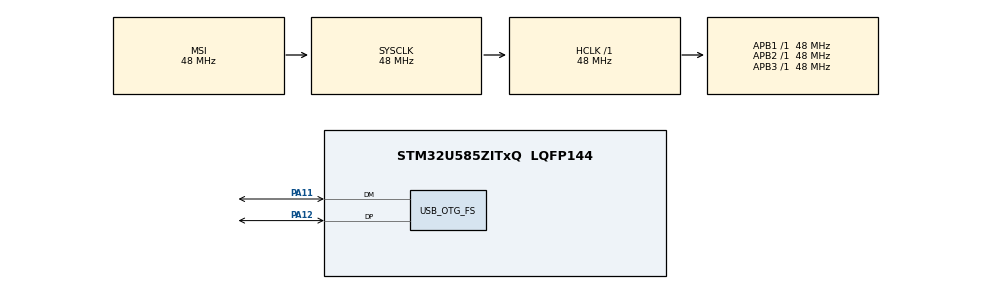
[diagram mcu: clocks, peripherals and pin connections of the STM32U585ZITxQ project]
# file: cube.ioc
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CORTEX_M33_NS.userName=CORTEX_M33
Mcu.Family=STM32U5
Mcu.Name=STM32U585ZITxQ
Mcu.Package=LQFP144
NVIC.OTG_FS_IRQn=true\:0\:0\:false\:false\:true\:true\:true\:true
NVIC.PriorityGroup=NVIC_PRIORITYGROUP_4
NVIC.TIM3_IRQn=true\:0\:0\:true\:false\:true\:false\:true\:true
NVIC.TimeBase=TIM3_IRQn
NVIC.TimeBaseIP=TIM3
PA11.Mode=Device_Only
PA11.Signal=USB_OTG_FS_DM
PA12.Mode=Device_Only
PA12.Signal=USB_OTG_FS_DP
PA13\ (JTMS/SWDIO).Mode=Serial_Wire
PA13\ (JTMS/SWDIO).Signal=DEBUG_JTMS-SWDIO
PA14\ (JTCK/SWCLK).Mode=Serial_Wire
PA14\ (JTCK/SWCLK).Signal=DEBUG_JTCK-SWCLK
PWR.PowerMode=PWR_SMPS_SUPPLY
ProjectManager.HeapSize=0x0
ProjectManager.StackSize=0x400
ProjectManager.TargetToolchain=STM32CubeIDE
RCC.ADCFreq_Value=16000000
RCC.AHBFreq_Value=48000000
RCC.APB1Freq_Value=48000000
RCC.APB1TimFreq_Value=48000000
RCC.APB2Freq_Value=48000000
RCC.APB2TimFreq_Value=48000000
RCC.APB3Freq_Value=48000000
RCC.CortexFreq_Value=48000000
RCC.DACCLockSelectionVirtual=RCC_DAC1CLKSOURCE_LSI
RCC.DACCLockSelectionVirtualString=RCC_DAC1CLKSOURCE_LSI
RCC.EPOD_VALUE=48000000
RCC.HCLKFreq_Value=48000000
RCC.HSE_VALUE=16000000
RCC.HSI48_VALUE=48000000
RCC.HSI_VALUE=16000000
RCC.LSE_VALUE=32768
RCC.LSIDIV_VALUE=32000
RCC.MSIClockRange=RCC_MSIRANGE_0
RCC.MSI_VALUE=48000000
RCC.SYSCLKFreq_VALUE=48000000
RCC.USBFreq_Value=48000000
RCC.VCOOutputFreq_Value=6192000000
USB_OTG_FS.VirtualMode=Device_Only
VP_ICACHE_VS_ICACHE.Mode=DirectMappedCache
VP_LPBAMQUEUE_VS_QUEUE.Mode=QUEUEMODE
VP_LPBAM_VS_SIG1.Mode=SmartRun
VP_LPBAM_VS_SIG4.Mode=LPDMA1
VP_PWR_VS_DBSignals.Mode=DisableDeadBatterySignals
VP_PWR_VS_LPOM.Mode=PowerOptimisation
VP_PWR_VS_SECSignals.Mode=Security/Privilege
VP_SYS_VS_tim3.Mode=TIM3
board=custom

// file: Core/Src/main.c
/* USER CODE BEGIN Header */
/**
  ******************************************************************************
  * @file           : main.c
  * @brief          : Main program body
  ******************************************************************************
  * @attention
  *
  * Copyright (c) 2023 STMicroelectronics.
  * All rights reserved.
  *
  * This software is licensed under terms that can be found in the LICENSE file
  * in the root directory of this software component.
  * If no LICENSE file comes with this software, it is provided AS-IS.
  *
  ******************************************************************************
  */
/* USER CODE END Header */
#include "main.h"
#include "icache.h"
#include "usb_otg.h"
#include "gpio.h"

void SystemClock_Config(void);
static void SystemPower_Config(void);

void SystemClock_Config(void)
{
  RCC_OscInitTypeDef RCC_OscInitStruct = {0};
  RCC_ClkInitTypeDef RCC_ClkInitStruct = {0};

  /** Configure the main internal regulator output voltage
  */
  if (HAL_PWREx_ControlVoltageScaling(PWR_REGULATOR_VOLTAGE_SCALE3) != HAL_OK)
  {
    Error_Handler();
  }

  /** Initializes the CPU, AHB and APB buses clocks
  */
  RCC_OscInitStruct.OscillatorType = RCC_OSCILLATORTYPE_HSI48|RCC_OSCILLATORTYPE_MSI;
  RCC_OscInitStruct.HSI48State = RCC_HSI48_ON;
  RCC_OscInitStruct.MSIState = RCC_MSI_ON;
  RCC_OscInitStruct.MSICalibrationValue = RCC_MSICALIBRATION_DEFAULT;
  RCC_OscInitStruct.MSIClockRange = RCC_MSIRANGE_0;
  RCC_OscInitStruct.PLL.PLLState = RCC_PLL_NONE;
  if (HAL_RCC_OscConfig(&RCC_OscInitStruct) != HAL_OK)
  {
    Error_Handler();
  }

  /** Initializes the CPU, AHB and APB buses clocks
  */
  RCC_ClkInitStruct.ClockType = RCC_CLOCKTYPE_HCLK|RCC_CLOCKTYPE_SYSCLK
                              |RCC_CLOCKTYPE_PCLK1|RCC_CLOCKTYPE_PCLK2
                              |RCC_CLOCKTYPE_PCLK3;
  RCC_ClkInitStruct.SYSCLKSource = RCC_SYSCLKSOURCE_MSI;
  RCC_ClkInitStruct.AHBCLKDivider = RCC_SYSCLK_DIV1;
  RCC_ClkInitStruct.APB1CLKDivider = RCC_HCLK_DIV1;
  RCC_ClkInitStruct.APB2CLKDivider = RCC_HCLK_DIV1;
  RCC_ClkInitStruct.APB3CLKDivider = RCC_HCLK_DIV1;

  if (HAL_RCC_ClockConfig(&RCC_ClkInitStruct, FLASH_LATENCY_1) != HAL_OK)
  {
    Error_Handler();
  }
}

/**
  * @brief Power Configuration
  * @retval None
  */
static void SystemPower_Config(void)
{

  /*
   * Disable the internal Pull-Up in Dead Battery pins of UCPD peripheral
   */
  HAL_PWREx_DisableUCPDDeadBattery();

  /*
   * Switch to SMPS regulator instead of LDO
   */
  if (HAL_PWREx_ConfigSupply(PWR_SMPS_SUPPLY) != HAL_OK)
  {
    Error_Handler();
  }
}

void HAL_TIM_PeriodElapsedCallback(TIM_HandleTypeDef *htim)
{
  if (htim->Instance == TIM3) {
    HAL_IncTick();
  }
}

void Error_Handler(void)
{
  /* USER CODE BEGIN Error_Handler_Debug */
  /* User can add his own implementation to report the HAL error return state */
  HAL_NVIC_SystemReset();
  /* USER CODE END Error_Handler_Debug */
}

#ifdef  USE_FULL_ASSERT
/**
  * @brief  Reports the name of the source file and the source line number
  *         where the assert_param error has occurred.
  * @param  file: pointer to the source file name
  * @param  line: assert_param error line source number
  * @retval None
  */
void assert_failed(uint8_t *file, uint32_t line)
{
  /* USER CODE BEGIN 6 */
  /* User can add his own implementation to report the file name and line number,
     ex: printf("Wrong parameters value: file %s on line %d\r\n", file, line) */
  HAL_NVIC_SystemReset();
  /* USER CODE END 6 */
}
#endif /* USE_FULL_ASSERT */
